VERSION "K24_CVT"

NS_ :

BS_:

BU_: IPC PCM UNKNOWN VSA

BO_ 401 PCM_0x191: 8 PCM
 SG_ AT_P_SWITCH : 0|1@1+ (1,0) [0|1] ""  IPC,VSA
 SG_ AT_R_SWITCH : 1|1@1+ (1,0) [0|1] ""  IPC,VSA
 SG_ AT_N_SWITCH : 2|1@1+ (1,0) [0|1] ""  IPC,VSA
 SG_ AT_D_SWITCH : 3|1@1+ (1,0) [0|1] ""  IPC,VSA
 SG_ AT_S_SWITCH : 4|1@1+ (1,0) [0|1] ""  IPC,VSA
 SG_ AT_L_SWITCH : 5|1@1+ (1,0) [0|1] ""  IPC,VSA
 SG_ RSVD_1 : 6|1@1+ (1,0) [0|1] ""  IPC,VSA
 SG_ TRANSMISSION_FAULT : 7|1@1+ (1,0) [0|1] ""  IPC,VSA
 SG_ RSVD_2 : 8|4@1+ (1,0) [0|15] ""  IPC,VSA
 SG_ LED_C : 12|1@1+ (1,0) [0|1] ""  IPC,VSA
 SG_ LED_B : 13|1@1+ (1,0) [0|1] ""  IPC,VSA
 SG_ LED_A : 14|1@1+ (1,0) [0|1] ""  IPC,VSA
 SG_ RSVD_3 : 15|1@1+ (1,0) [0|1] ""  IPC,VSA
 SG_ RSVD_4 : 16|1@1+ (1,0) [0|1] ""  IPC,VSA
 SG_ ECON_MODE_INDICATOR : 17|1@1+ (1,0) [0|1] ""  IPC,VSA
 SG_ RSVD_5 : 18|1@1+ (1,0) [0|1] ""  IPC,VSA
 SG_ MANUAL_MODE_INDICATOR : 19|1@1+ (1,0) [0|1] ""  IPC,VSA
 SG_ CVT_CRITICAL_FAULT : 20|1@1+ (1,0) [0|1] ""  IPC,VSA
 SG_ RSVD_6 : 21|1@1+ (1,0) [0|1] ""  IPC,VSA
 SG_ COMMUNICATION_SPEED_FAULT : 22|1@1+ (1,0) [0|1] ""  IPC,VSA
 SG_ RANGE_DISPLAY_CONTROL : 23|1@1+ (1,0) [0|1] ""  IPC,VSA
 SG_ PULLEY_RATIO : 24|8@1+ (0.015625,0) [0|3.984375] "ratio"  IPC,VSA
 SG_ CVT_RATIO_TARGET : 32|8@1+ (0.015625,0) [0|3.984375] "ratio"  IPC,VSA
 SG_ RANGE_DISPLAY : 40|4@1+ (1,0) [0|15] ""  IPC,VSA
 SG_ RSVD_7 : 44|2@1+ (1,0) [0|3] ""  IPC,VSA
 SG_ CVT_FLUID_SERVICE_RESET : 46|1@1+ (1,0) [0|1] ""  IPC,VSA
 SG_ CVT_FLUID_SERVICE_DUE : 47|1@1+ (1,0) [0|1] ""  IPC,VSA
 SG_ CVT_CONTROL_SCHEDULE : 48|8@1+ (1,0) [0|255] ""  IPC,VSA
 SG_ CHECKSUM : 56|4@1+ (1,0) [0|15] ""  IPC,VSA
 SG_ COUNTER : 60|2@1+ (1,0) [0|3] ""  IPC,VSA
 SG_ CVT_RATIO_RANGE_QUALIFIED : 62|1@1+ (1,0) [0|1] ""  IPC,VSA
 SG_ CVT_AUTO_STOP_HOLD : 63|1@1+ (1,0) [0|1] ""  IPC,VSA
VAL_ 401 CVT_CONTROL_SCHEDULE 17 "MANUAL_16_GEAR_STEP_1_7" 18 "MANUAL_16_GEAR_STEP_1_7" 19 "MANUAL_16_GEAR_STEP_1_7" 20 "MANUAL_16_GEAR_STEP_1_7" 21 "MANUAL_16_GEAR_STEP_1_7" 22 "MANUAL_16_GEAR_STEP_1_7" 23 "MANUAL_16_GEAR_STEP_1_7" 33 "ALT_MANUAL_32_GEAR_STEP_1_7" 34 "ALT_MANUAL_32_GEAR_STEP_1_7" 35 "ALT_MANUAL_32_GEAR_STEP_1_7" 36 "ALT_MANUAL_32_GEAR_STEP_1_7" 37 "ALT_MANUAL_32_GEAR_STEP_1_7" 38 "ALT_MANUAL_32_GEAR_STEP_1_7" 39 "ALT_MANUAL_32_GEAR_STEP_1_7" 81 "OVERRIDE_BRANCH" 90 "OVERRIDE_BRANCH" 127 "FAULT_LATCH_OVERRIDE" ;
VAL_ 401 RANGE_DISPLAY 0 "BLANK" 1 "P" 2 "R" 3 "N" 4 "D" 6 "UNRESOLVED" 7 "L" 8 "UNRESOLVED" 10 "S_0X0A" 15 "ALL_SEGMENTS" ;
VAL_ 401 MANUAL_MODE_INDICATOR 0 "OFF" 1 "ON" ;
VAL_ 401 ECON_MODE_INDICATOR 0 "OFF" 1 "ON" ;
VAL_ 401 LED_A 0 "OFF" 1 "ON" ;
VAL_ 401 LED_B 0 "OFF" 1 "ON" ;
VAL_ 401 LED_C 0 "OFF" 1 "ON" ;
VAL_ 401 AT_L_SWITCH 0 "OFF" 1 "ON" ;
VAL_ 401 AT_S_SWITCH 0 "OFF" 1 "ON" ;
VAL_ 401 AT_D_SWITCH 0 "OFF" 1 "ON" ;
VAL_ 401 AT_N_SWITCH 0 "OFF" 1 "ON" ;
VAL_ 401 AT_R_SWITCH 0 "OFF" 1 "ON" ;
VAL_ 401 AT_P_SWITCH 0 "OFF" 1 "ON" ;

CM_ SG_ 401 AT_P_SWITCH "CANCVT: A/T P Switch";
CM_ SG_ 401 AT_R_SWITCH "CANCVT: A/T R Switch";
CM_ SG_ 401 AT_N_SWITCH "CANCVT: A/T N Switch";
CM_ SG_ 401 AT_D_SWITCH "CANCVT: A/T D Switch";
CM_ SG_ 401 AT_S_SWITCH "CANCVT: A/T S Switch";
CM_ SG_ 401 AT_L_SWITCH "CANCVT: A/T L Switch";
CM_ SG_ 401 LED_A "CANCVT: LED A";
CM_ SG_ 401 LED_B "CANCVT: LED B";
CM_ SG_ 401 LED_C "CANCVT: LED C";
CM_ SG_ 401 ECON_MODE_INDICATOR "CANCVT: ECON Mode Indicator";
CM_ SG_ 401 MANUAL_MODE_INDICATOR "CANCVT: Manual Mode Indicator";
CM_ SG_ 401 PULLEY_RATIO "CANCVT: Pulley Ratio";
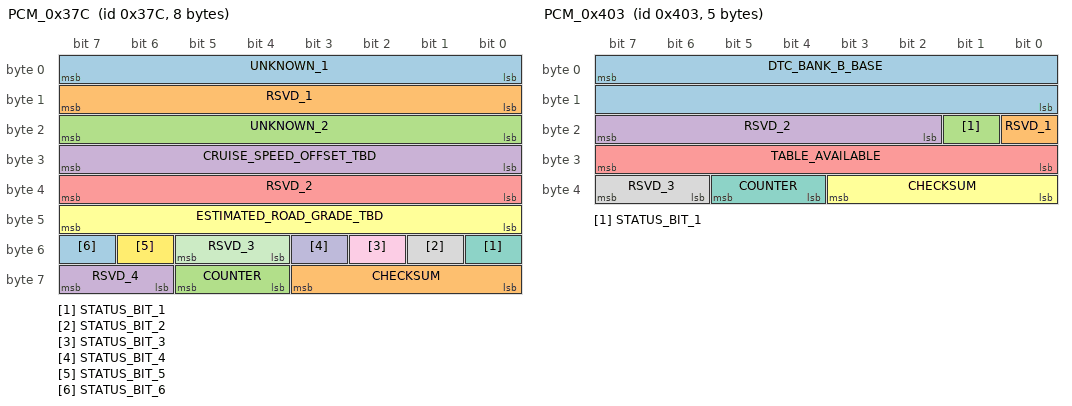
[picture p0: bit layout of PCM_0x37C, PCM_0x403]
BO_ 892 PCM_0x37C: 8 PCM
 SG_ UNKNOWN_1 : 0|8@1+ (1,0) [0|255] ""  UNKNOWN
 SG_ RSVD_1 : 8|8@1+ (1,0) [0|255] ""  UNKNOWN
 SG_ UNKNOWN_2 : 16|8@1+ (1,0) [0|255] ""  UNKNOWN
 SG_ CRUISE_SPEED_OFFSET_TBD : 24|8@1- (0.1,0) [-12.8|12.700000000000001] "km/h"  UNKNOWN
 SG_ RSVD_2 : 32|8@1+ (1,0) [0|255] ""  UNKNOWN
 SG_ ESTIMATED_ROAD_GRADE_TBD : 40|8@1+ (1,0) [0|255] ""  UNKNOWN
 SG_ STATUS_BIT_1 : 48|1@1+ (1,0) [0|1] ""  UNKNOWN
 SG_ STATUS_BIT_2 : 49|1@1+ (1,0) [0|1] ""  UNKNOWN
 SG_ STATUS_BIT_3 : 50|1@1+ (1,0) [0|1] ""  UNKNOWN
 SG_ STATUS_BIT_4 : 51|1@1+ (1,0) [0|1] ""  UNKNOWN
 SG_ RSVD_3 : 52|2@1+ (1,0) [0|3] ""  UNKNOWN
 SG_ STATUS_BIT_5 : 54|1@1+ (1,0) [0|1] ""  UNKNOWN
 SG_ STATUS_BIT_6 : 55|1@1+ (1,0) [0|1] ""  UNKNOWN
 SG_ CHECKSUM : 56|4@1+ (1,0) [0|15] ""  UNKNOWN
 SG_ COUNTER : 60|2@1+ (1,0) [0|3] ""  UNKNOWN
 SG_ RSVD_4 : 62|2@1+ (1,0) [0|3] ""  UNKNOWN

BO_ 1027 PCM_0x403: 5 PCM
 SG_ DTC_BANK_B_BASE : 7|16@0+ (1,0) [0|65535] ""  UNKNOWN
 SG_ RSVD_1 : 16|1@1+ (1,0) [0|1] ""  UNKNOWN
 SG_ STATUS_BIT_1 : 17|1@1+ (1,0) [0|1] ""  UNKNOWN
 SG_ RSVD_2 : 18|6@1+ (1,0) [0|63] ""  UNKNOWN
 SG_ TABLE_AVAILABLE : 24|8@1+ (1,0) [0|255] ""  UNKNOWN
 SG_ CHECKSUM : 32|4@1+ (1,0) [0|15] ""  UNKNOWN
 SG_ COUNTER : 36|2@1+ (1,0) [0|3] ""  UNKNOWN
 SG_ RSVD_3 : 38|2@1+ (1,0) [0|3] ""  UNKNOWN

BO_ 1039 PCM_0x40F: 8 PCM
 SG_ MULTIPLEX_PAGE M : 0|4@1+ (1,0) [0|15] ""  UNKNOWN
 SG_ MULTIPLEX_GROUP : 4|2@1+ (1,0) [0|3] ""  UNKNOWN
 SG_ DIAGNOSTIC_EVENT_STATE : 6|2@1+ (1,0) [0|3] ""  UNKNOWN
 SG_ UNKNOWN_1 m0 : 8|8@1+ (1,0) [0|255] ""  UNKNOWN
 SG_ UNKNOWN_2 m1 : 8|8@1+ (1,0) [0|255] ""  UNKNOWN
 SG_ P02_ENGINE_SPEED m2 : 15|16@0+ (1,0) [0|65535] "rpm"  UNKNOWN
 SG_ P03_OUTPUT_SHAFT_DRIVEN_PULLEY_SPEED_RPM m3 : 15|16@0+ (1,0) [0|65535] "rpm"  UNKNOWN
 SG_ P04_INTAKE_AIR_TEMPERATURE m4 : 8|8@1+ (1,-40) [-40|215] "degC"  UNKNOWN
 SG_ P05_APP_SENSOR m5 : 8|8@1+ (0.5,0) [0|127.5] "%"  UNKNOWN
 SG_ P06_DRIVE_PULLEY_SOL_COMMAND m6 : 8|8@1+ (0.005,0) [0|1.2750000000000001] "A"  UNKNOWN
 SG_ P07_PRESSURE_CONTROL_SOL_COMMAND m7 : 8|8@1+ (0.005,0) [0|1.2750000000000001] "A"  UNKNOWN
 SG_ RSVD_1 m8 : 8|8@1+ (1,0) [0|255] ""  UNKNOWN
 SG_ P00_FRZDTC m0 : 23|16@0+ (1,0) [0|65535] ""  UNKNOWN
 SG_ UNKNOWN_3 m1 : 16|8@1+ (1,0) [0|255] ""  UNKNOWN
 SG_ P04_BARO_SENSOR_V m4 : 16|8@1+ (0.0196,0) [0|4.998] "V"  UNKNOWN
 SG_ P05_CVTF_TEMP_SENSOR_V m5 : 16|8@1+ (0.0196,0) [0|4.998] "V"  UNKNOWN
 SG_ P06_DRIVE_PULLEY_SOL_ACTUAL m6 : 16|8@1+ (0.005,0) [0|1.2750000000000001] "A"  UNKNOWN
 SG_ P07_PRESSURE_CONTROL_SOL_ACTUAL m7 : 16|8@1+ (0.005,0) [0|1.2750000000000001] "A"  UNKNOWN
 SG_ RSVD_2 m8 : 16|8@1+ (1,0) [0|255] ""  UNKNOWN
 SG_ UNKNOWN_4 m1 : 24|8@1+ (1,0) [0|255] ""  UNKNOWN
 SG_ P02_TORQUE_CONVERTER_TURBINE_SPEED m2 : 31|16@0+ (1,0) [0|65535] "rpm"  UNKNOWN
 SG_ P03_SECONDARY_SHAFT_SPEED m3 : 24|8@1+ (1,0) [0|255] "km/h"  UNKNOWN
 SG_ P04_MAP_SENSOR_V m4 : 24|8@1+ (0.0196,0) [0|4.998] "V"  UNKNOWN
 SG_ P05_DRIVEN_PULLEY_PRESSURE_SENSOR_V m5 : 24|8@1+ (0.0196,0) [0|4.998] "V"  UNKNOWN
 SG_ P06_DRIVEN_PULLEY_SOL_COMMAND m6 : 24|8@1+ (0.005,0) [0|1.2750000000000001] "A"  UNKNOWN
 SG_ RSVD_3 m7 : 24|5@1+ (1,0) [0|31] ""  UNKNOWN
 SG_ RSVD_4 m8 : 24|8@1+ (1,0) [0|255] ""  UNKNOWN
 SG_ P07_SHIFT_SOL_OP m7 : 29|1@1+ (1,0) [0|1] ""  UNKNOWN
 SG_ P07_SHIFT_SOL_B m7 : 30|1@1+ (1,0) [0|1] ""  UNKNOWN
 SG_ P07_SHIFT_SOL_A m7 : 31|1@1+ (1,0) [0|1] ""  UNKNOWN
 SG_ UNKNOWN_5 m0 : 32|8@1+ (1,0) [0|255] ""  UNKNOWN
 SG_ UNKNOWN_6 m1 : 32|8@1+ (1,0) [0|255] ""  UNKNOWN
 SG_ P03_ABS_WHEEL_SPEED m3 : 32|8@1+ (1,0) [0|255] "km/h"  UNKNOWN
 SG_ P04_TP_SENSOR_1 m4 : 32|8@1+ (0.0196,0) [0|4.998] "V"  UNKNOWN
 SG_ P05_INCLINATION_SENSOR_OUTPUT_VOLTAGE m5 : 32|8@1+ (0.0196,0) [0|4.998] "V"  UNKNOWN
 SG_ P06_DRIVEN_PULLEY_SOL_ACTUAL m6 : 32|8@1+ (0.005,0) [0|1.2750000000000001] "A"  UNKNOWN
 SG_ RSVD_5 m7 : 32|6@1+ (1,0) [0|63] ""  UNKNOWN
 SG_ RSVD_6 m8 : 32|8@1+ (1,0) [0|255] ""  UNKNOWN
 SG_ P07_INHIBITOR_SOL m7 : 38|1@1+ (1,0) [0|1] ""  UNKNOWN
 SG_ P07_SHIFT_LOCK_SOL m7 : 39|1@1+ (1,0) [0|1] ""  UNKNOWN
 SG_ RSVD_13 m0 : 47|16@0+ (1,0) [0|65535] ""  UNKNOWN
 SG_ UNKNOWN_8 m1 : 40|8@1+ (1,0) [0|255] ""  UNKNOWN
 SG_ P02_INPUT_SHAFT_DRIVE_PULLEY_SPEED_RPM m2 : 47|16@0+ (1,0) [0|65535] "rpm"  UNKNOWN
 SG_ P03_VEHICLE_SPEED m3 : 40|8@1+ (1,0) [0|255] "km/h"  UNKNOWN
 SG_ P04_ECT_SENSOR_V m4 : 40|8@1+ (0.0196,0) [0|4.998] "V"  UNKNOWN
 SG_ P05_ELECTRIC_OIL_PUMP_RPM m5 : 40|8@1+ (50,0) [0|12750] "rpm"  UNKNOWN
 SG_ P06_LCC_LINEAR_SOL_COMMAND m6 : 40|8@1+ (0.005,0) [0|1.2750000000000001] "A"  UNKNOWN
 SG_ RSVD_7 m7 : 40|2@1+ (1,0) [0|3] ""  UNKNOWN
 SG_ RSVD_8 m8 : 40|8@1+ (1,0) [0|255] ""  UNKNOWN
 SG_ P07_AT_L_SWITCH m7 : 42|1@1+ (1,0) [0|1] ""  UNKNOWN
 SG_ P07_AT_S_SWITCH m7 : 43|1@1+ (1,0) [0|1] ""  UNKNOWN
 SG_ P07_AT_D_SWITCH m7 : 44|1@1+ (1,0) [0|1] ""  UNKNOWN
 SG_ P07_AT_N_SWITCH m7 : 45|1@1+ (1,0) [0|1] ""  UNKNOWN
 SG_ P07_AT_R_SWITCH m7 : 46|1@1+ (1,0) [0|1] ""  UNKNOWN
 SG_ P07_AT_P_SWITCH m7 : 47|1@1+ (1,0) [0|1] ""  UNKNOWN
 SG_ RSVD_14 m1 : 48|8@1+ (1,0) [0|255] ""  UNKNOWN
 SG_ P03_DIRECTION_OF_DRIVE_PULLEY_ROTATION m3 : 48|2@1+ (1,0) [0|3] ""  UNKNOWN
 SG_ P04_BATTERY_VOLTAGE m4 : 48|8@1+ (0.1,0) [0|25.5] "V"  UNKNOWN
 SG_ RSVD_9 m5 : 48|6@1+ (1,0) [0|63] ""  UNKNOWN
 SG_ P06_LCC_LINEAR_SOL_ACTUAL m6 : 48|8@1+ (0.005,0) [0|1.2750000000000001] "A"  UNKNOWN
 SG_ RSVD_10 m7 : 48|3@1+ (1,0) [0|7] ""  UNKNOWN
 SG_ RSVD_11 m8 : 48|8@1+ (1,0) [0|255] ""  UNKNOWN
 SG_ P03_NON_CREEP_CONTROL_STATUS m3 : 50|1@1+ (1,0) [0|1] ""  UNKNOWN
 SG_ P03_FUEL_CUT_DECEL m3 : 51|1@1+ (1,0) [0|1] ""  UNKNOWN
 SG_ P07_PARK_PIN_SWITCH m7 : 51|1@1+ (1,0) [0|1] ""  UNKNOWN
 SG_ P03_DIRECTION_OF_SECONDARY_SHAFT_ROTATION m3 : 52|2@1+ (1,0) [0|3] ""  UNKNOWN
 SG_ RSVD_12 m7 : 52|2@1+ (1,0) [0|3] ""  UNKNOWN
 SG_ P03_DIRECTION_OF_TURBINE_ROTATION m3 : 54|2@1+ (1,0) [0|3] ""  UNKNOWN
 SG_ P05_BRAKE_SWITCH m5 : 54|1@1+ (1,0) [0|1] ""  UNKNOWN
 SG_ P07_REVERSE_SWITCH_ATPRVS m7 : 54|1@1+ (1,0) [0|1] ""  UNKNOWN
 SG_ P05_SCS m5 : 55|1@1+ (1,0) [0|1] ""  UNKNOWN
 SG_ P07_FORWARD_SWITCH m7 : 55|1@1+ (1,0) [0|1] ""  UNKNOWN
 SG_ CHECKSUM : 56|4@1+ (1,0) [0|15] ""  UNKNOWN
 SG_ COUNTER : 60|2@1+ (1,0) [0|3] ""  UNKNOWN
 SG_ RSVD_15 : 62|2@1+ (1,0) [0|3] ""  UNKNOWN
VAL_ 1039 P07_FORWARD_SWITCH 0 "OFF" 1 "ON" ;
VAL_ 1039 P05_SCS 0 "OPEN" 1 "SHORT" ;
VAL_ 1039 P07_REVERSE_SWITCH_ATPRVS 0 "OFF" 1 "ON" ;
VAL_ 1039 P05_BRAKE_SWITCH 0 "OFF" 1 "ON" ;
VAL_ 1039 P03_DIRECTION_OF_TURBINE_ROTATION 0 "STOP" 1 "NORMAL_ROTATION" 2 "INVERSE_ROTATION" 3 "NOT_AVAILABLE" ;
VAL_ 1039 P03_DIRECTION_OF_SECONDARY_SHAFT_ROTATION 0 "STOP" 1 "FORWARD" 2 "REVERSE" 3 "NOT_AVAILABLE" ;
VAL_ 1039 P07_PARK_PIN_SWITCH 0 "OFF" 1 "ON" ;
VAL_ 1039 P03_FUEL_CUT_DECEL 0 "OTHER" 1 "FUELCUT" ;
VAL_ 1039 P03_NON_CREEP_CONTROL_STATUS 0 "OTHER" 1 "NON_CREEP" ;
VAL_ 1039 P03_DIRECTION_OF_DRIVE_PULLEY_ROTATION 0 "STOP" 1 "FORWARD" 2 "REVERSE" 3 "NOT_AVAILABLE" ;
VAL_ 1039 P07_AT_P_SWITCH 0 "OFF" 1 "ON" ;
VAL_ 1039 P07_AT_R_SWITCH 0 "OFF" 1 "ON" ;
VAL_ 1039 P07_AT_N_SWITCH 0 "OFF" 1 "ON" ;
VAL_ 1039 P07_AT_D_SWITCH 0 "OFF" 1 "ON" ;
VAL_ 1039 P07_AT_S_SWITCH 0 "OFF" 1 "ON" ;
VAL_ 1039 P07_AT_L_SWITCH 0 "OFF" 1 "ON" ;
VAL_ 1039 P07_SHIFT_LOCK_SOL 0 "OFF" 1 "ON" ;
VAL_ 1039 P07_INHIBITOR_SOL 0 "OFF" 1 "ON" ;
VAL_ 1039 P07_SHIFT_SOL_A 0 "OFF" 1 "ON" ;
VAL_ 1039 P07_SHIFT_SOL_B 0 "OFF" 1 "ON" ;
SG_MUL_VAL_ 1039 UNKNOWN_1 MULTIPLEX_PAGE 0-0;
SG_MUL_VAL_ 1039 UNKNOWN_2 MULTIPLEX_PAGE 1-1;
SG_MUL_VAL_ 1039 P02_ENGINE_SPEED MULTIPLEX_PAGE 2-2;
SG_MUL_VAL_ 1039 P03_OUTPUT_SHAFT_DRIVEN_PULLEY_SPEED_RPM MULTIPLEX_PAGE 3-3;
SG_MUL_VAL_ 1039 P04_INTAKE_AIR_TEMPERATURE MULTIPLEX_PAGE 4-4;
SG_MUL_VAL_ 1039 P05_APP_SENSOR MULTIPLEX_PAGE 5-5;
SG_MUL_VAL_ 1039 P06_DRIVE_PULLEY_SOL_COMMAND MULTIPLEX_PAGE 6-6;
SG_MUL_VAL_ 1039 P07_PRESSURE_CONTROL_SOL_COMMAND MULTIPLEX_PAGE 7-7;
SG_MUL_VAL_ 1039 RSVD_1 MULTIPLEX_PAGE 8-15;
SG_MUL_VAL_ 1039 P00_FRZDTC MULTIPLEX_PAGE 0-0;
SG_MUL_VAL_ 1039 UNKNOWN_3 MULTIPLEX_PAGE 1-1;
SG_MUL_VAL_ 1039 P04_BARO_SENSOR_V MULTIPLEX_PAGE 4-4;
SG_MUL_VAL_ 1039 P05_CVTF_TEMP_SENSOR_V MULTIPLEX_PAGE 5-5;
SG_MUL_VAL_ 1039 P06_DRIVE_PULLEY_SOL_ACTUAL MULTIPLEX_PAGE 6-6;
SG_MUL_VAL_ 1039 P07_PRESSURE_CONTROL_SOL_ACTUAL MULTIPLEX_PAGE 7-7;
SG_MUL_VAL_ 1039 RSVD_2 MULTIPLEX_PAGE 8-15;
SG_MUL_VAL_ 1039 UNKNOWN_4 MULTIPLEX_PAGE 1-1;
SG_MUL_VAL_ 1039 P02_TORQUE_CONVERTER_TURBINE_SPEED MULTIPLEX_PAGE 2-2;
SG_MUL_VAL_ 1039 P03_SECONDARY_SHAFT_SPEED MULTIPLEX_PAGE 3-3;
SG_MUL_VAL_ 1039 P04_MAP_SENSOR_V MULTIPLEX_PAGE 4-4;
SG_MUL_VAL_ 1039 P05_DRIVEN_PULLEY_PRESSURE_SENSOR_V MULTIPLEX_PAGE 5-5;
SG_MUL_VAL_ 1039 P06_DRIVEN_PULLEY_SOL_COMMAND MULTIPLEX_PAGE 6-6;
SG_MUL_VAL_ 1039 RSVD_3 MULTIPLEX_PAGE 7-7;
SG_MUL_VAL_ 1039 RSVD_4 MULTIPLEX_PAGE 8-15;
SG_MUL_VAL_ 1039 P07_SHIFT_SOL_OP MULTIPLEX_PAGE 7-7;
SG_MUL_VAL_ 1039 P07_SHIFT_SOL_B MULTIPLEX_PAGE 7-7;
SG_MUL_VAL_ 1039 P07_SHIFT_SOL_A MULTIPLEX_PAGE 7-7;
SG_MUL_VAL_ 1039 UNKNOWN_5 MULTIPLEX_PAGE 0-0;
SG_MUL_VAL_ 1039 UNKNOWN_6 MULTIPLEX_PAGE 1-1;
SG_MUL_VAL_ 1039 P03_ABS_WHEEL_SPEED MULTIPLEX_PAGE 3-3;
SG_MUL_VAL_ 1039 P04_TP_SENSOR_1 MULTIPLEX_PAGE 4-4;
SG_MUL_VAL_ 1039 P05_INCLINATION_SENSOR_OUTPUT_VOLTAGE MULTIPLEX_PAGE 5-5;
SG_MUL_VAL_ 1039 P06_DRIVEN_PULLEY_SOL_ACTUAL MULTIPLEX_PAGE 6-6;
SG_MUL_VAL_ 1039 RSVD_5 MULTIPLEX_PAGE 7-7;
SG_MUL_VAL_ 1039 RSVD_6 MULTIPLEX_PAGE 8-15;
SG_MUL_VAL_ 1039 P07_INHIBITOR_SOL MULTIPLEX_PAGE 7-7;
SG_MUL_VAL_ 1039 P07_SHIFT_LOCK_SOL MULTIPLEX_PAGE 7-7;
SG_MUL_VAL_ 1039 RSVD_13 MULTIPLEX_PAGE 0-0;
SG_MUL_VAL_ 1039 UNKNOWN_8 MULTIPLEX_PAGE 1-1;
SG_MUL_VAL_ 1039 P02_INPUT_SHAFT_DRIVE_PULLEY_SPEED_RPM MULTIPLEX_PAGE 2-2;
SG_MUL_VAL_ 1039 P03_VEHICLE_SPEED MULTIPLEX_PAGE 3-3;
SG_MUL_VAL_ 1039 P04_ECT_SENSOR_V MULTIPLEX_PAGE 4-4;
SG_MUL_VAL_ 1039 P05_ELECTRIC_OIL_PUMP_RPM MULTIPLEX_PAGE 5-5;
SG_MUL_VAL_ 1039 P06_LCC_LINEAR_SOL_COMMAND MULTIPLEX_PAGE 6-6;
SG_MUL_VAL_ 1039 RSVD_7 MULTIPLEX_PAGE 7-7;
SG_MUL_VAL_ 1039 RSVD_8 MULTIPLEX_PAGE 8-15;
SG_MUL_VAL_ 1039 P07_AT_L_SWITCH MULTIPLEX_PAGE 7-7;
SG_MUL_VAL_ 1039 P07_AT_S_SWITCH MULTIPLEX_PAGE 7-7;
SG_MUL_VAL_ 1039 P07_AT_D_SWITCH MULTIPLEX_PAGE 7-7;
SG_MUL_VAL_ 1039 P07_AT_N_SWITCH MULTIPLEX_PAGE 7-7;
SG_MUL_VAL_ 1039 P07_AT_R_SWITCH MULTIPLEX_PAGE 7-7;
SG_MUL_VAL_ 1039 P07_AT_P_SWITCH MULTIPLEX_PAGE 7-7;
SG_MUL_VAL_ 1039 RSVD_14 MULTIPLEX_PAGE 1-1;
SG_MUL_VAL_ 1039 P03_DIRECTION_OF_DRIVE_PULLEY_ROTATION MULTIPLEX_PAGE 3-3;
SG_MUL_VAL_ 1039 P04_BATTERY_VOLTAGE MULTIPLEX_PAGE 4-4;
SG_MUL_VAL_ 1039 RSVD_9 MULTIPLEX_PAGE 5-5;
SG_MUL_VAL_ 1039 P06_LCC_LINEAR_SOL_ACTUAL MULTIPLEX_PAGE 6-6;
SG_MUL_VAL_ 1039 RSVD_10 MULTIPLEX_PAGE 7-7;
SG_MUL_VAL_ 1039 RSVD_11 MULTIPLEX_PAGE 8-15;
SG_MUL_VAL_ 1039 P03_NON_CREEP_CONTROL_STATUS MULTIPLEX_PAGE 3-3;
SG_MUL_VAL_ 1039 P03_FUEL_CUT_DECEL MULTIPLEX_PAGE 3-3;
SG_MUL_VAL_ 1039 P07_PARK_PIN_SWITCH MULTIPLEX_PAGE 7-7;
SG_MUL_VAL_ 1039 P03_DIRECTION_OF_SECONDARY_SHAFT_ROTATION MULTIPLEX_PAGE 3-3;
SG_MUL_VAL_ 1039 RSVD_12 MULTIPLEX_PAGE 7-7;
SG_MUL_VAL_ 1039 P03_DIRECTION_OF_TURBINE_ROTATION MULTIPLEX_PAGE 3-3;
SG_MUL_VAL_ 1039 P05_BRAKE_SWITCH MULTIPLEX_PAGE 5-5;
SG_MUL_VAL_ 1039 P07_REVERSE_SWITCH_ATPRVS MULTIPLEX_PAGE 7-7;
SG_MUL_VAL_ 1039 P05_SCS MULTIPLEX_PAGE 5-5;
SG_MUL_VAL_ 1039 P07_FORWARD_SWITCH MULTIPLEX_PAGE 7-7;

CM_ SG_ 1039 P02_ENGINE_SPEED "CANCVT: Engine Speed";
CM_ SG_ 1039 P02_TORQUE_CONVERTER_TURBINE_SPEED "CANCVT: Torque Converter Turbine Speed";
CM_ SG_ 1039 P02_INPUT_SHAFT_DRIVE_PULLEY_SPEED_RPM "CANCVT: Input Shaft(Drive Pulley) Speed rpm";
CM_ SG_ 1039 P03_OUTPUT_SHAFT_DRIVEN_PULLEY_SPEED_RPM "CANCVT: Output Shaft(Driven Pulley) Speed rpm";
CM_ SG_ 1039 P03_SECONDARY_SHAFT_SPEED "CANCVT: Secondary Shaft Speed";
CM_ SG_ 1039 P03_ABS_WHEEL_SPEED "CANCVT: ABS Wheel Speed";
CM_ SG_ 1039 P03_VEHICLE_SPEED "CANCVT: Vehicle Speed";
CM_ SG_ 1039 P03_DIRECTION_OF_DRIVE_PULLEY_ROTATION "CANCVT: Direction of Drive Pulley Rotation";
CM_ SG_ 1039 P03_NON_CREEP_CONTROL_STATUS "CANCVT: Non Creep Control Status";
CM_ SG_ 1039 P03_FUEL_CUT_DECEL "CANCVT: Fuel Cut Decel";
CM_ SG_ 1039 P03_DIRECTION_OF_SECONDARY_SHAFT_ROTATION "CANCVT: Direction of Secondary-shaft Rotation";
CM_ SG_ 1039 P03_DIRECTION_OF_TURBINE_ROTATION "CANCVT: Direction of Turbine Rotation";
CM_ SG_ 1039 P04_INTAKE_AIR_TEMPERATURE "CANCVT: Intake Air Temperature";
CM_ SG_ 1039 P04_BARO_SENSOR_V "CANCVT: BARO SENSOR (V)";
CM_ SG_ 1039 P04_MAP_SENSOR_V "CANCVT: MAP Sensor (V)";
CM_ SG_ 1039 P04_TP_SENSOR_1 "CANCVT: TP Sensor (1)";
CM_ SG_ 1039 P04_ECT_SENSOR_V "CANCVT: ECT Sensor (V)";
CM_ SG_ 1039 P04_BATTERY_VOLTAGE "CANCVT: Battery Voltage";
CM_ SG_ 1039 P05_APP_SENSOR "CANCVT: APP Sensor (%)";
CM_ SG_ 1039 P05_CVTF_TEMP_SENSOR_V "CANCVT: CVTF Temp Sensor (V)";
CM_ SG_ 1039 P05_DRIVEN_PULLEY_PRESSURE_SENSOR_V "CANCVT: Driven Pulley Pressure Sensor(V)";
CM_ SG_ 1039 P05_INCLINATION_SENSOR_OUTPUT_VOLTAGE "CANCVT: Inclination Sensor Output Voltage";
CM_ SG_ 1039 P05_ELECTRIC_OIL_PUMP_RPM "CANCVT: Electric Oil Pump(rpm)";
CM_ SG_ 1039 P05_BRAKE_SWITCH "CANCVT: Brake Switch";
CM_ SG_ 1039 P06_DRIVE_PULLEY_SOL_COMMAND "CANCVT: Drive Pulley Sol Command";
CM_ SG_ 1039 P06_DRIVE_PULLEY_SOL_ACTUAL "CANCVT: Drive Pulley Sol Actual";
CM_ SG_ 1039 P06_DRIVEN_PULLEY_SOL_COMMAND "CANCVT: Driven Pulley Sol Command";
CM_ SG_ 1039 P06_DRIVEN_PULLEY_SOL_ACTUAL "CANCVT: Driven Pulley Sol Actual";
CM_ SG_ 1039 P06_LCC_LINEAR_SOL_COMMAND "CANCVT: LCC Linear Sol Command";
CM_ SG_ 1039 P06_LCC_LINEAR_SOL_ACTUAL "CANCVT: LCC Linear Sol Actual";
CM_ SG_ 1039 P07_PRESSURE_CONTROL_SOL_COMMAND "CANCVT: Pressure Control Sol Command";
CM_ SG_ 1039 P07_PRESSURE_CONTROL_SOL_ACTUAL "CANCVT: Pressure Control Sol Actual";
CM_ SG_ 1039 P07_SHIFT_SOL_OP "CANCVT: Shift Sol O/P";
CM_ SG_ 1039 P07_SHIFT_SOL_B "CANCVT: Shift Sol B";
CM_ SG_ 1039 P07_SHIFT_SOL_A "CANCVT: Shift Sol A";
CM_ SG_ 1039 P07_INHIBITOR_SOL "CANCVT: Inhibitor Sol";
CM_ SG_ 1039 P07_SHIFT_LOCK_SOL "CANCVT: Shift Lock Sol";
CM_ SG_ 1039 P07_AT_L_SWITCH "CANCVT: A/T L Switch";
CM_ SG_ 1039 P07_AT_S_SWITCH "CANCVT: A/T S Switch";
CM_ SG_ 1039 P07_AT_D_SWITCH "CANCVT: A/T D Switch";
CM_ SG_ 1039 P07_AT_N_SWITCH "CANCVT: A/T N Switch";
CM_ SG_ 1039 P07_AT_R_SWITCH "CANCVT: A/T R Switch";
CM_ SG_ 1039 P07_AT_P_SWITCH "CANCVT: A/T P Switch";
CM_ SG_ 1039 P07_PARK_PIN_SWITCH "CANCVT: Park Pin Switch";
CM_ SG_ 1039 P07_REVERSE_SWITCH_ATPRVS "CANCVT: Reverse Switch(ATPRVS)";
CM_ SG_ 1039 P07_FORWARD_SWITCH "CANCVT: Forward Switch";
CM_ SG_ 1039 P05_SCS "CANCVT: SCS";
CM_ SG_ 1039 P00_FRZDTC "CANFI: FRZDTC";
